AUTOSAR XML (schema 4-2-1)
package /ComponentTypes
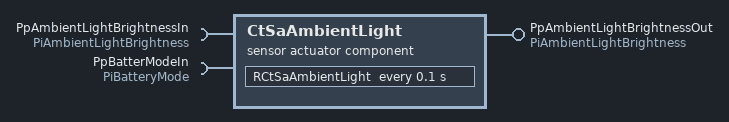
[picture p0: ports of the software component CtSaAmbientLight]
  sensor actuator sw component type CtSaAmbientLight
    provide port PpAmbientLightBrightnessOut: nonqueued-sender-com-spec{data-element=DeAmbientLightBrightness, init-value=constant-reference=CDarkLight}, provided-interface=PiAmbientLightBrightness
    require port PpAmbientLightBrightnessIn: nonqueued-receiver-com-spec{data-element=DeAmbientLightBrightness, filter=data-filter-type=ALWAYS, init-value=constant-reference=CDarkLight}, required-interface=PiAmbientLightBrightness
    require port PpBatterModeIn: mode-switch-receiver-com-spec{enhanced-mode-api=false, supports-asynchronous-mode-switch=false}, required-interface=PiBatteryMode
    behavior CtSaAmbientLight_InternalBehavior: data-type-mapping=ApMappingSet
      timing event TMT_Runnable: disabled-mode=PpBatterModeIn.BatteryModes.BATTERY_LOW, start-on-event=RCtSaAmbientLight, period=0.1
      runnable RCtSaAmbientLight
        data-receive-point-by-arguments:
          access REC_PpAmbientLightBrightnessIn_DeAmbientLightBrightness: accessed-variable=PpAmbientLightBrightnessIn.DeAmbientLightBrightness
        data-send-points:
          access SEND_PpAmbientLightBrightnessOut_DeAmbientLightBrightness: accessed-variable=PpAmbientLightBrightnessOut.DeAmbientLightBrightness
  swc implementation CtSaAmbientLight_Implementation: behavior=CtSaAmbientLight_InternalBehavior
    code-descriptors:
      code Default: artifact-descriptors=autosar-engineering-object={short-label=Default, category=SWSRC}
